AUTOSAR XML (schema 4-2-1)
standard types defined: boolean, uint8, uint16, uint32, uint64, sint8, sint16, sint32, sint64, float32, float64
package /ZARXML_DATA_TYPES
  5 x impl type:
    data_u8_64: category=ARRAY
      element Element: array-size=64, array-size-semantics=FIXED-SIZE, implementation-data-type=uint8
    data_u8_2048: category=ARRAY
      element Element: array-size=2048, array-size-semantics=FIXED-SIZE, implementation-data-type=uint8
    SUpdateShortServiceReq: category=STRUCTURE
      7 x element, all with category=TYPE_REFERENCE:
        msgId: implementation-data-type=uint16
        msgSize: implementation-data-type=uint16
        memoryType: implementation-data-type=uint8
        memoryCmd: implementation-data-type=uint8
        sid: implementation-data-type=uint8
        length: implementation-data-type=uint32
        data: implementation-data-type=data_u8_64
    SUpdateLongServiceReq: category=STRUCTURE
      7 x element, all with category=TYPE_REFERENCE:
        msgId: implementation-data-type=uint16
        msgSize: implementation-data-type=uint16
        memoryType: implementation-data-type=uint8
        memoryCmd: implementation-data-type=uint8
        sid: implementation-data-type=uint8
        length: implementation-data-type=uint32
        data: implementation-data-type=data_u8_2048
    SUpdateShortServiceResp: category=STRUCTURE
      7 x element, all with category=TYPE_REFERENCE:
        msgId: implementation-data-type=uint16
        msgSize: implementation-data-type=uint16
        sid: implementation-data-type=uint8
        length: implementation-data-type=uint16
        responseCode: implementation-data-type=uint8
        NRC: implementation-data-type=uint8
        data: implementation-data-type=data_u8_64
package /ZARXML_PORT_IF
  sender receiver interface UpdateShortServiceReq: invalidation-policy=UpdateShortServiceReqData
    data UpdateShortServiceReqData: type=SUpdateShortServiceReq
  sender receiver interface UpdateLongServiceReq: invalidation-policy=UpdateLongServiceReqData
    data UpdateLongServiceReqData: type=SUpdateLongServiceReq
  sender receiver interface UpdateShortServiceResp: invalidation-policy=UpdateShortServiceRespData
    data UpdateShortServiceRespData: type=SUpdateShortServiceResp
  client server interface UclInitShutdown
    operation Initialize: possible-error=UclInitShutdown/E_OK
    operation Shutdown: possible-error=UclInitShutdown/E_OK
    error E_OK: error-code=0
  client server interface UclCmplibCmd
    operation OnCommand: possible-error=UclCmplibCmd/E_OK
      arg Cmd: type=uint8, direction=IN
    error E_OK: error-code=0
  client server interface UclSystemCallbacks
    operation ErrorNotification
      arg DLInst: type=uint8, direction=IN
      arg ErrorCode: type=sint32, direction=IN
    operation LinkStatusChanged
      arg DLInst: type=uint8, direction=IN
      arg Status: type=sint32, direction=IN
  sender receiver interface UclTxStatuses
package /ZARXML_CMP
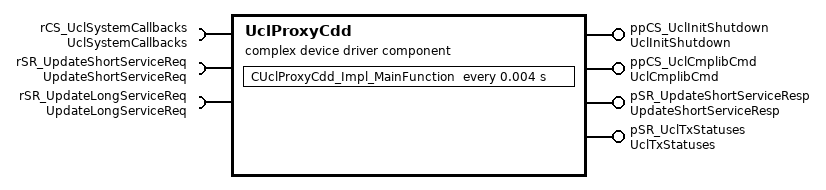
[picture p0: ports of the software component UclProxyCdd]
  complex device driver sw component type UclProxyCdd
    provide port ppCS_UclInitShutdown: provided-interface=UclInitShutdown
    provide port ppCS_UclCmplibCmd: provided-interface=UclCmplibCmd
    require port rCS_UclSystemCallbacks: required-interface=UclSystemCallbacks
    provide port pSR_UpdateShortServiceResp: nonqueued-sender-com-spec{data-element=UpdateShortServiceRespData, init-value={short-label=SUpdateShortServiceResp, fields=[uint16:0, uint16:0, uint8:0, uint16:0, uint8:0, uint8:0, data_u8_64:64 x uint8:0]}}, provided-interface=UpdateShortServiceResp
    require port rSR_UpdateShortServiceReq: nonqueued-receiver-com-spec{data-element=UpdateShortServiceReqData, init-value={short-label=SUpdateShortServiceReq, fields=[uint16:0, uint16:0, uint8:0, uint8:0, uint8:0, uint32:0, data_u8_64:64 x uint8:0]}}, required-interface=UpdateShortServiceReq
    require port rSR_UpdateLongServiceReq: nonqueued-receiver-com-spec{data-element=UpdateLongServiceReqData, init-value={short-label=SUpdateLongServiceReq, fields=[uint16:0, uint16:0, uint8:0, uint8:0, uint8:0, uint32:0, data_u8_2048:2048 x uint8:0]}}, required-interface=UpdateLongServiceReq
    provide port pSR_UclTxStatuses: provided-interface=UclTxStatuses
    behavior UclProxyCdd_IB: handle-termination-and-restart=NO-SUPPORT
      operation invoked event OI_ppCS_UclInitShutdown_Initialize: start-on-event=CUclProxyCdd_Impl_Initialize, operation=ppCS_UclInitShutdown.Initialize
      operation invoked event OI_ppCS_UclInitShutdown_Shutdown: start-on-event=CUclProxyCdd_Impl_Shutdown, operation=ppCS_UclInitShutdown.Shutdown
      operation invoked event OI_ppCS_UclCmplibCmd_OnCommand: start-on-event=CUclProxyCdd_Impl_OnCommand, operation=ppCS_UclCmplibCmd.OnCommand
      data received event DRE_rSR_UpdateShortServiceReq_UpdateShortServiceReqData_OnDre_UpdateShortServiceReq: start-on-event=OnDre_UpdateShortServiceReq, data=rSR_UpdateShortServiceReq.UpdateShortServiceReqData
      data received event DRE_rSR_UpdateLongServiceReq_UpdateLongServiceReqData_OnDre_UpdateLongServiceReq: start-on-event=OnDre_UpdateLongServiceReq, data=rSR_UpdateLongServiceReq.UpdateLongServiceReqData
      timing event TE_CUclProxyCdd_Impl_MainFunction: start-on-event=CUclProxyCdd_Impl_MainFunction, period=0.004
      6 x runnable:
        CUclProxyCdd_Impl_MainFunction
          data-receive-point-by-arguments:
            access READ_rSR_UpdateShortServiceReq_UpdateShortServiceReqData: accessed-variable=rSR_UpdateShortServiceReq.UpdateShortServiceReqData
            access READ_rSR_UpdateLongServiceReq_UpdateLongServiceReqData: accessed-variable=rSR_UpdateLongServiceReq.UpdateLongServiceReqData
          data-send-points:
            access WRITE_pSR_UpdateShortServiceResp_UpdateShortServiceRespData: accessed-variable=pSR_UpdateShortServiceResp.UpdateShortServiceRespData
          sync call CALL_rCS_UclSystemCallbacks_ErrorNotification: operation=rCS_UclSystemCallbacks.ErrorNotification, timeout=0.0
          sync call CALL_rCS_UclSystemCallbacks_LinkStatusChanged: operation=rCS_UclSystemCallbacks.LinkStatusChanged, timeout=0.0
        CUclProxyCdd_Impl_Initialize
        CUclProxyCdd_Impl_Shutdown
        CUclProxyCdd_Impl_OnCommand
        OnDre_UpdateShortServiceReq
        OnDre_UpdateLongServiceReq
  swc implementation UclProxyCdd_Implementation: behavior=UclProxyCdd_IB
    code-descriptors:
      code Default: artifact-descriptors=autosar-engineering-object={short-label=Default, category=SWSRC}
